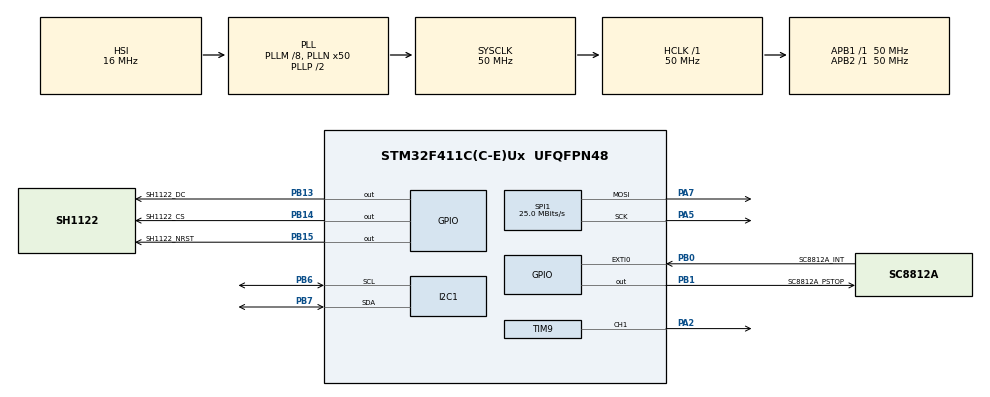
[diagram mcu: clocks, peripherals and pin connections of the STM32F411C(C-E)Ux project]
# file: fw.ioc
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FREERTOS.Queues01=extiQueue,8,void*,0,Dynamic,NULL,NULL
FREERTOS.Tasks01=defaultTask,24,128,StartDefaultTask,As weak,NULL,Dynamic,NULL,NULL;extiCallbackTas,8,128,startExtiCallbackTask,As external,NULL,Dynamic,NULL,NULL;uiTask,24,128,startUiTask,As external,NULL,Dynamic,NULL,NULL
I2C1.I2C_Mode=I2C_Fast
Mcu.Family=STM32F4
Mcu.Name=STM32F411C(C-E)Ux
Mcu.Package=UFQFPN48
NVIC.PriorityGroup=NVIC_PRIORITYGROUP_4
PA13.Mode=Serial_Wire
PA13.Signal=SYS_JTMS-SWDIO
PA14.Mode=Serial_Wire
PA14.Signal=SYS_JTCK-SWCLK
PA2.Signal=S_TIM9_CH1
PA5.Mode=TX_Only_Simplex_Unidirect_Master
PA5.Signal=SPI1_SCK
PA7.Mode=TX_Only_Simplex_Unidirect_Master
PA7.Signal=SPI1_MOSI
PB0.GPIO_Label=SC8812A_INT
PB0.GPIO_ModeDefaultEXTI=GPIO_MODE_IT_FALLING
PB0.GPIO_PuPd=GPIO_PULLUP
PB0.Signal=GPXTI0
PB1.GPIO_Label=SC8812A_PSTOP
PB1.Signal=GPIO_Output
PB13.GPIO_Label=SH1122_DC
PB13.Signal=GPIO_Output
PB14.GPIO_Label=SH1122_CS
PB14.Signal=GPIO_Output
PB15.GPIO_Label=SH1122_NRST
PB15.Signal=GPIO_Output
PB6.Mode=I2C
PB6.Signal=I2C1_SCL
PB7.Mode=I2C
PB7.Signal=I2C1_SDA
ProjectManager.HeapSize=0x200
ProjectManager.StackSize=0x400
ProjectManager.TargetToolchain=Other Toolchains (GPDSC)
RCC.48MHZClocksFreq_Value=25000000
RCC.AHBFreq_Value=50000000
RCC.APB1Freq_Value=50000000
RCC.APB1TimFreq_Value=50000000
RCC.APB2Freq_Value=50000000
RCC.APB2TimFreq_Value=50000000
RCC.CortexFreq_Value=50000000
RCC.HCLKFreq_Value=50000000
RCC.HSE_VALUE=25000000
RCC.HSI_VALUE=16000000
RCC.LSE_VALUE=32768
RCC.PLLM=8
RCC.PLLN=50
RCC.SYSCLKFreq_VALUE=50000000
RCC.SYSCLKSource=RCC_SYSCLKSOURCE_PLLCLK
RCC.VCOOutputFreq_Value=100000000
SH.S_TIM9_CH1.0=TIM9_CH1,PWM Generation1 CH1
SPI1.CLKPhase=SPI_PHASE_2EDGE
SPI1.CLKPolarity=SPI_POLARITY_HIGH
SPI1.CalculateBaudRate=25.0 MBits/s
SPI1.Direction=SPI_DIRECTION_2LINES
SPI1.Mode=SPI_MODE_MASTER
SPI1.VirtualType=VM_MASTER
TIM9.Channel-PWM\ Generation1\ CH1=TIM_CHANNEL_1
VP_FREERTOS_VS_CMSIS_V2.Mode=CMSIS_V2
board=custom

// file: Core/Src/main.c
/* USER CODE BEGIN Header */
/**
  ******************************************************************************
  * @file           : main.c
  * @brief          : Main program body
  ******************************************************************************
  * @attention
  *
  * <h2><center>&copy; Copyright (c) 2020 STMicroelectronics.
  * All rights reserved.</center></h2>
  *
  * This software component is licensed by ST under Ultimate Liberty license
  * SLA0044, the "License"; You may not use this file except in compliance with
  * the License. You may obtain a copy of the License at:
  *                             www.st.com/SLA0044
  *
  ******************************************************************************
  */
/* USER CODE END Header */

#include "main.h"
#include "cmsis_os.h"

/* USER CODE BEGIN Includes */
#include "program.hpp"
/* USER CODE END Includes */

I2C_HandleTypeDef hi2c1;

SPI_HandleTypeDef hspi1;

TIM_HandleTypeDef htim9;

/* Definitions for defaultTask */
osThreadId_t defaultTaskHandle;
const osThreadAttr_t defaultTask_attributes = {
  .name = "defaultTask",
  .priority = (osPriority_t) osPriorityNormal,
  .stack_size = 128
};
/* Definitions for extiCallbackTas */
osThreadId_t extiCallbackTasHandle;
const osThreadAttr_t extiCallbackTas_attributes = {
  .name = "extiCallbackTas",
  .priority = (osPriority_t) osPriorityLow,
  .stack_size = 128
};
/* Definitions for uiTask */
osThreadId_t uiTaskHandle;
const osThreadAttr_t uiTask_attributes = {
  .name = "uiTask",
  .priority = (osPriority_t) osPriorityNormal,
  .stack_size = 128
};
/* Definitions for extiQueue */
osMessageQueueId_t extiQueueHandle;
const osMessageQueueAttr_t extiQueue_attributes = {
  .name = "extiQueue"
};

void SystemClock_Config(void);
static void MX_GPIO_Init(void);
static void MX_I2C1_Init(void);
static void MX_TIM9_Init(void);
static void MX_SPI1_Init(void);
void StartDefaultTask(void *argument);
extern void startExtiCallbackTask(void *argument);
extern void startUiTask(void *argument);

int main(void)
{

  /* MCU Configuration--------------------------------------------------------*/

  /* Reset of all peripherals, Initializes the Flash interface and the Systick. */
  HAL_Init();

  /* Configure the system clock */
  SystemClock_Config();

  /* Initialize all configured peripherals */
  MX_GPIO_Init();
  MX_I2C1_Init();
  MX_TIM9_Init();
  MX_SPI1_Init();
  /* Init scheduler */
  osKernelInitialize();

  /* Create the queue(s) */
  /* creation of extiQueue */
  extiQueueHandle = osMessageQueueNew (8, sizeof(void*), &extiQueue_attributes);

  /* Create the thread(s) */
  /* creation of defaultTask */
  defaultTaskHandle = osThreadNew(StartDefaultTask, NULL, &defaultTask_attributes);

  /* creation of extiCallbackTas */
  extiCallbackTasHandle = osThreadNew(startExtiCallbackTask, NULL, &extiCallbackTas_attributes);

  /* creation of uiTask */
  uiTaskHandle = osThreadNew(startUiTask, NULL, &uiTask_attributes);

  /* Start scheduler */
  osKernelStart();

  /* We should never get here as control is now taken by the scheduler */

  /* Infinite loop */
  while (1)
  {

  }
}

void SystemClock_Config(void)
{
  RCC_OscInitTypeDef RCC_OscInitStruct = {0};
  RCC_ClkInitTypeDef RCC_ClkInitStruct = {0};

  /** Configure the main internal regulator output voltage
  */
  __HAL_RCC_PWR_CLK_ENABLE();
  __HAL_PWR_VOLTAGESCALING_CONFIG(PWR_REGULATOR_VOLTAGE_SCALE1);
  /** Initializes the CPU, AHB and APB busses clocks
  */
  RCC_OscInitStruct.OscillatorType = RCC_OSCILLATORTYPE_HSI;
  RCC_OscInitStruct.HSIState = RCC_HSI_ON;
  RCC_OscInitStruct.HSICalibrationValue = RCC_HSICALIBRATION_DEFAULT;
  RCC_OscInitStruct.PLL.PLLState = RCC_PLL_ON;
  RCC_OscInitStruct.PLL.PLLSource = RCC_PLLSOURCE_HSI;
  RCC_OscInitStruct.PLL.PLLM = 8;
  RCC_OscInitStruct.PLL.PLLN = 50;
  RCC_OscInitStruct.PLL.PLLP = RCC_PLLP_DIV2;
  RCC_OscInitStruct.PLL.PLLQ = 4;
  if (HAL_RCC_OscConfig(&RCC_OscInitStruct) != HAL_OK)
  {
    Error_Handler();
  }
  /** Initializes the CPU, AHB and APB busses clocks
  */
  RCC_ClkInitStruct.ClockType = RCC_CLOCKTYPE_HCLK|RCC_CLOCKTYPE_SYSCLK
                              |RCC_CLOCKTYPE_PCLK1|RCC_CLOCKTYPE_PCLK2;
  RCC_ClkInitStruct.SYSCLKSource = RCC_SYSCLKSOURCE_PLLCLK;
  RCC_ClkInitStruct.AHBCLKDivider = RCC_SYSCLK_DIV1;
  RCC_ClkInitStruct.APB1CLKDivider = RCC_HCLK_DIV1;
  RCC_ClkInitStruct.APB2CLKDivider = RCC_HCLK_DIV1;

  if (HAL_RCC_ClockConfig(&RCC_ClkInitStruct, FLASH_LATENCY_1) != HAL_OK)
  {
    Error_Handler();
  }
}

static void MX_I2C1_Init(void)
{

  hi2c1.Instance = I2C1;
  hi2c1.Init.ClockSpeed = 400000;
  hi2c1.Init.DutyCycle = I2C_DUTYCYCLE_2;
  hi2c1.Init.OwnAddress1 = 0;
  hi2c1.Init.AddressingMode = I2C_ADDRESSINGMODE_7BIT;
  hi2c1.Init.DualAddressMode = I2C_DUALADDRESS_DISABLE;
  hi2c1.Init.OwnAddress2 = 0;
  hi2c1.Init.GeneralCallMode = I2C_GENERALCALL_DISABLE;
  hi2c1.Init.NoStretchMode = I2C_NOSTRETCH_DISABLE;
  if (HAL_I2C_Init(&hi2c1) != HAL_OK)
  {
    Error_Handler();
  }

}

static void MX_SPI1_Init(void)
{

  /* SPI1 parameter configuration*/
  hspi1.Instance = SPI1;
  hspi1.Init.Mode = SPI_MODE_MASTER;
  hspi1.Init.Direction = SPI_DIRECTION_2LINES;
  hspi1.Init.DataSize = SPI_DATASIZE_8BIT;
  hspi1.Init.CLKPolarity = SPI_POLARITY_HIGH;
  hspi1.Init.CLKPhase = SPI_PHASE_2EDGE;
  hspi1.Init.NSS = SPI_NSS_SOFT;
  hspi1.Init.BaudRatePrescaler = SPI_BAUDRATEPRESCALER_2;
  hspi1.Init.FirstBit = SPI_FIRSTBIT_MSB;
  hspi1.Init.TIMode = SPI_TIMODE_DISABLE;
  hspi1.Init.CRCCalculation = SPI_CRCCALCULATION_DISABLE;
  hspi1.Init.CRCPolynomial = 10;
  if (HAL_SPI_Init(&hspi1) != HAL_OK)
  {
    Error_Handler();
  }

}

static void MX_TIM9_Init(void)
{

  TIM_OC_InitTypeDef sConfigOC = {0};

  htim9.Instance = TIM9;
  htim9.Init.Prescaler = 0;
  htim9.Init.CounterMode = TIM_COUNTERMODE_UP;
  htim9.Init.Period = 0;
  htim9.Init.ClockDivision = TIM_CLOCKDIVISION_DIV1;
  htim9.Init.AutoReloadPreload = TIM_AUTORELOAD_PRELOAD_DISABLE;
  if (HAL_TIM_PWM_Init(&htim9) != HAL_OK)
  {
    Error_Handler();
  }
  sConfigOC.OCMode = TIM_OCMODE_PWM1;
  sConfigOC.Pulse = 0;
  sConfigOC.OCPolarity = TIM_OCPOLARITY_HIGH;
  sConfigOC.OCFastMode = TIM_OCFAST_DISABLE;
  if (HAL_TIM_PWM_ConfigChannel(&htim9, &sConfigOC, TIM_CHANNEL_1) != HAL_OK)
  {
    Error_Handler();
  }
  HAL_TIM_MspPostInit(&htim9);

}

static void MX_GPIO_Init(void)
{
  GPIO_InitTypeDef GPIO_InitStruct = {0};

  /* GPIO Ports Clock Enable */
  __HAL_RCC_GPIOA_CLK_ENABLE();
  __HAL_RCC_GPIOB_CLK_ENABLE();

  /*Configure GPIO pin Output Level */
  HAL_GPIO_WritePin(GPIOB, SC8812A_PSTOP_Pin|SH1122_DC_Pin|SH1122_CS_Pin|SH1122_NRST_Pin, GPIO_PIN_RESET);

  /*Configure GPIO pin : SC8812A_INT_Pin */
  GPIO_InitStruct.Pin = SC8812A_INT_Pin;
  GPIO_InitStruct.Mode = GPIO_MODE_IT_FALLING;
  GPIO_InitStruct.Pull = GPIO_PULLUP;
  HAL_GPIO_Init(SC8812A_INT_GPIO_Port, &GPIO_InitStruct);

  /*Configure GPIO pins : SC8812A_PSTOP_Pin SH1122_DC_Pin SH1122_CS_Pin SH1122_NRST_Pin */
  GPIO_InitStruct.Pin = SC8812A_PSTOP_Pin|SH1122_DC_Pin|SH1122_CS_Pin|SH1122_NRST_Pin;
  GPIO_InitStruct.Mode = GPIO_MODE_OUTPUT_PP;
  GPIO_InitStruct.Pull = GPIO_NOPULL;
  GPIO_InitStruct.Speed = GPIO_SPEED_FREQ_LOW;
  HAL_GPIO_Init(GPIOB, &GPIO_InitStruct);

}

__weak void StartDefaultTask(void *argument)
{
  for(;;)
  {
    osDelay(1);
  }
}

void Error_Handler(void)
{
}

/************************ (C) COPYRIGHT STMicroelectronics *****END OF FILE****/
